# STM32WLE4C8U6 register map
File version: 1.0
Registers are 32-bit, access not given, reset 0x0 unless marked. A register's access mark holds for its fields unless they carry their own. Offsets are from the block's base; [hi:lo] are bit positions; {n}, {i} and the like mark numbered series.

## I2C1
Base 0x40005400
Same registers: I2C2 0x40005800, I2C3 0x40005C00
0x00 CR1
  [23] PECEN, [22] ALERTEN, [21] SMBDEN, [20] SMBHEN, [19] GCEN, [18] WUPEN, [17] NOSTRETCH, [16] SBC, [15] RXDMAEN, [14] TXDMAEN, [31:13] s, [12] ANFOFF, [11:8] DNF, [7] ERRIE, [6] TCIE, [5] STOPIE, [4] NACKIE, [3] ADDRIE, [2] RXIE, [1] TXIE, [0] PE
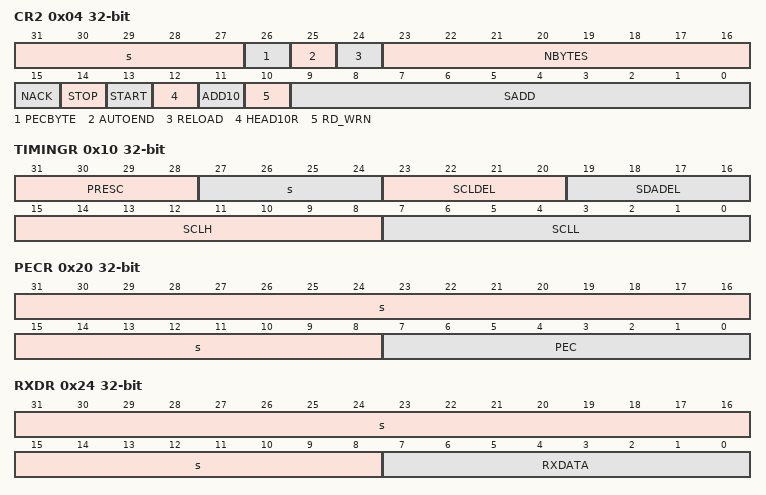
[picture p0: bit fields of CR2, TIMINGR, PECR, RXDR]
0x04 CR2
  [31:27] s, [26] PECBYTE, [25] AUTOEND, [24] RELOAD, [23:16] NBYTES, [15] NACK, [14] STOP, [13] START, [12] HEAD10R, [11] ADD10, [10] RD_WRN, [9:0] SADD
0x08 OAR1
  [15] OA1EN, [31:11] s, [10] OA1MODE, [9:0] OA1
0x0C OAR2
  [15] OA2EN, [10:8] OA2MSK, [7:1] OA2, [31:0] s
0x10 TIMINGR
  [31:28] PRESC, [27:24] s, [23:20] SCLDEL, [19:16] SDADEL, [15:8] SCLH, [7:0] SCLL
0x14 TIMEOUTR
  [31] TEXTEN, [27:16] TIMEOUTB, [15] TIMOUTEN, [30:13] s, [12] TIDLE, [11:0] TIMEOUTA
0x18 ISR
  [23:17] ADDCODE, [16] DIR, [15] BUSY, [31:14] s, [13] ALERT, [12] TIMEOUT, [11] PECERR, [10] OVR, [9] ARLO, [8] BERR, [7] TCR, [6] TC, [5] STOPF, [4] NACKF, [3] ADDR, [2] RXNE, [1] TXIS, [0] TXE
0x1C ICR
  [13] ALERTCF, [12] TIMOUTCF, [11] PECCF, [10] OVRCF, [9] ARLOCF, [8] BERRCF, [5] STOPCF, [4] NACKCF, [3] ADDRCF, [31:0] s
0x20 PECR
  [31:8] s, [7:0] PEC
0x24 RXDR
  [31:8] s, [7:0] RXDATA
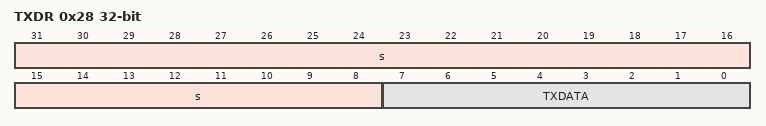
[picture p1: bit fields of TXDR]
0x28 TXDR
  [31:8] s, [7:0] TXDATA

## DAC
Base 0x40007400
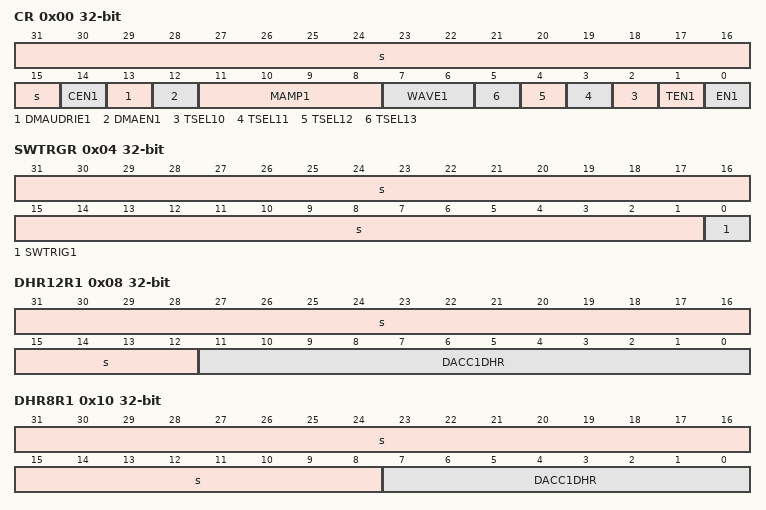
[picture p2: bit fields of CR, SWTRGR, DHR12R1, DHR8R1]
0x00 CR
  [31:15] s, [14] CEN1, [13] DMAUDRIE1, [12] DMAEN1, [11:8] MAMP1, [7:6] WAVE1, [n-8] TSEL{n} (n=10..13), [1] TEN1, [0] EN1
0x04 SWTRGR
  [31:1] s, [0] SWTRIG1
0x08 DHR12R1
  [31:12] s, [11:0] DACC1DHR
0x0C DHR12L1
  [15:4] DACC1DHR, [31:0] s
0x10 DHR8R1
  [31:8] s, [7:0] DACC1DHR
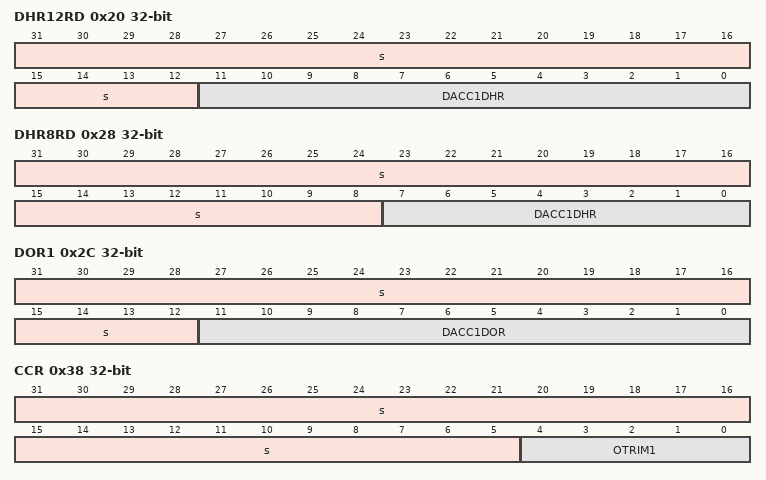
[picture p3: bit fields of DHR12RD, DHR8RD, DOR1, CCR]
0x20 DHR12RD
  [31:12] s, [11:0] DACC1DHR
0x24 DHR12LD
  [15:4] DACC1DHR, [31:0] s
0x28 DHR8RD
  [31:8] s, [7:0] DACC1DHR
0x2C DOR1
  [31:12] s, [11:0] DACC1DOR
0x34 SR
  [15] BWST1, [14] CAL_FLAG1, [13] DMAUDR1, [31:0] s
0x38 CCR
  [31:5] s, [4:0] OTRIM1
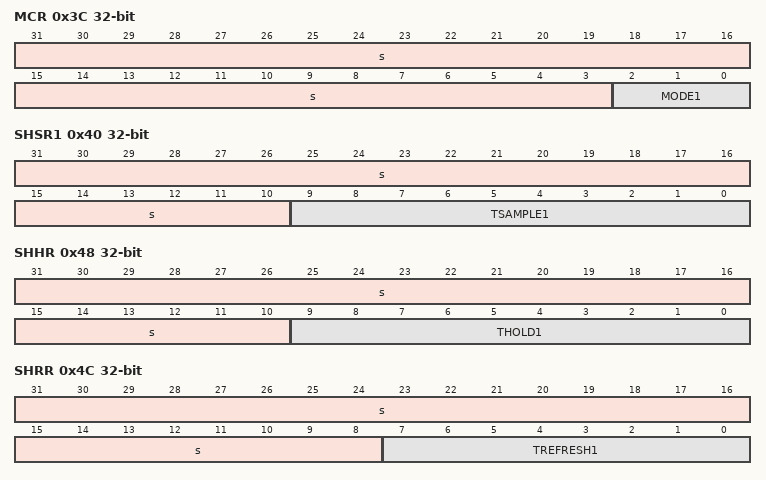
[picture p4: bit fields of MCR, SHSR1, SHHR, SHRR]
0x3C MCR
  [31:3] s, [2:0] MODE1
0x40 SHSR1
  [31:10] s, [9:0] TSAMPLE1
0x48 SHHR
  [31:10] s, [9:0] THOLD1
0x4C SHRR
  [31:8] s, [7:0] TREFRESH1

## LPTIM1
Base 0x40007C00
0x00 CR1
  [11] UIFREMAP, [31:10] s, [9:8] CKD, [7] ARPE, [6:5] CMS, [4] DIR, [3] OPM, [2] URS, [1] UDIS, [0] CEN
0x04 CR2
  [23:20] MMS2, [2n+6] OIS{n} (n=1..6), [13] OIS3N, [11] OIS2N, [9] OIS1N, [7] TI1S, [6:4] MMS, [3] CCDS, [2] CCUS, [31:1] s, [0] CCPC
0x08 SMCR
  [31:17] s, [15] ETP, [14] ECE, [13:12] ETPS, [11:8] ETF, [7] MSM, [21:4] TS, [3] OCCS, [16:0] SMS
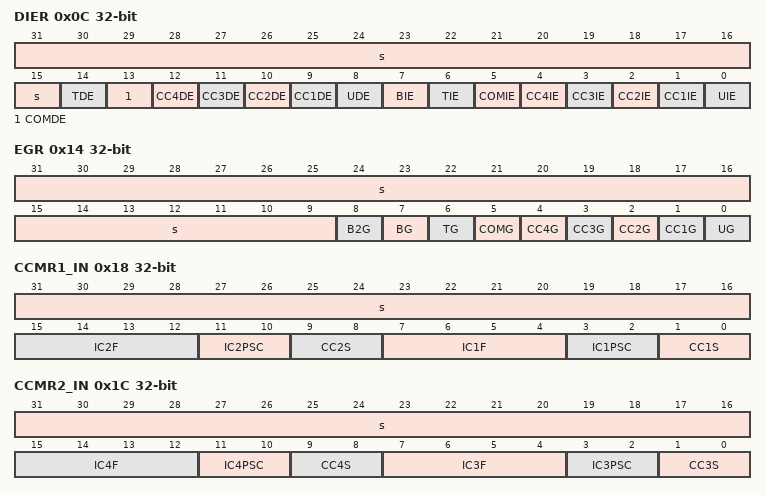
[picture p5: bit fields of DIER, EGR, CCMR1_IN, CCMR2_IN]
0x0C DIER
  [31:15] s, [14] TDE, [13] COMDE, [n+8] CC{n}DE (n=1..4), [8] UDE, [7] BIE, [6] TIE, [5] COMIE, [n] CC{n}IE (n=1..4), [0] UIE
0x10 SR
  [17] CC6IF, [16] CC5IF, [31:14] s, [13] SBIF, [n+8] CC{n}OF (n=1..4), [8] B2IF, [7] BIF, [6] TIF, [5] COMIF, [n] CC{n}IF (n=1..4), [0] UIF
0x14 EGR
  [31:9] s, [8] B2G, [7] BG, [6] TG, [5] COMG, [n] CC{n}G (n=1..4), [0] UG
0x18 CCMR1_OUT
  [31:17] s, [15] OC2CE, [24:12] OC2M, [11] OC2PE, [10] OC2FE, [9:8] CC2S, [7] OC1CE, [16:4] OC1M, [3] OC1PE, [2] OC1FE, [1:0] CC1S
0x18 CCMR1_IN
  [31:16] s, [15:12] IC2F, [11:10] IC2PSC, [9:8] CC2S, [7:4] IC1F, [3:2] IC1PSC, [1:0] CC1S
0x1C CCMR2_OUT
  [31:17] s, [15] OC4CE, [24:12] OC4M, [11] OC4PE, [10] OC4FE, [9:8] CC4S, [7] OC3CE, [16:4] OC3M, [3] OC3PE, [2] OC3FE, [1:0] CC3S
0x1C CCMR2_IN
  [31:16] s, [15:12] IC4F, [11:10] IC4PSC, [9:8] CC4S, [7:4] IC3F, [3:2] IC3PSC, [1:0] CC3S
0x20 CCER
  [4n-3] CC{n}P (n=1..6), [4n-4] CC{n}E (n=1..6), [4n-1] CC{n}NP (n=1..4), [31:14] s, [10] CC3NE, [6] CC2NE, [2] CC1NE
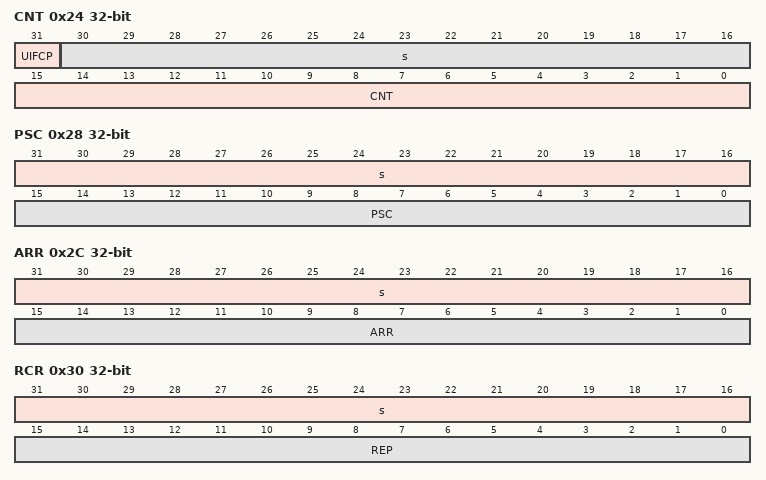
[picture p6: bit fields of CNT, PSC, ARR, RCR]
0x24 CNT
  [31] UIFCP, [30:16] s, [15:0] CNT
0x28 PSC
  [31:16] s, [15:0] PSC
0x2C ARR
  [31:16] s, [15:0] ARR
0x30 RCR
  [31:16] s, [15:0] REP
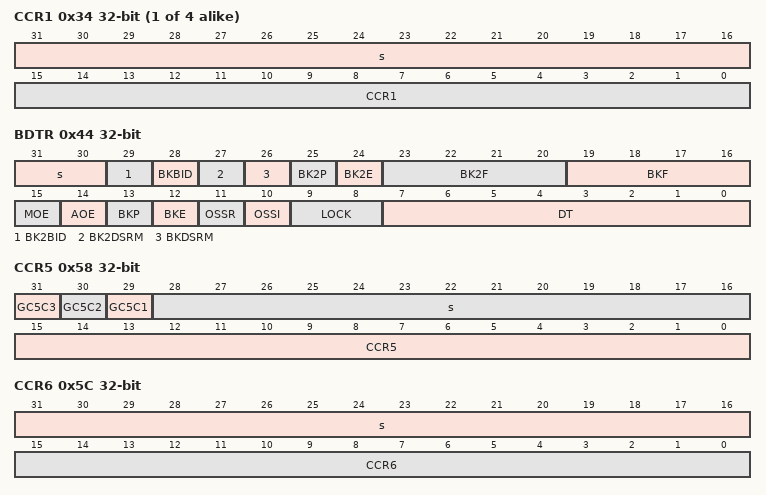
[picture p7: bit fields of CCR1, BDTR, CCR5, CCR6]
{0x30+4i} CCR{i} (i=1..4)
  [31:16] s, [15:0] CCR{i}
0x44 BDTR
  [31:30] s, [29] BK2BID, [28] BKBID, [27] BK2DSRM, [26] BKDSRM, [25] BK2P, [24] BK2E, [23:20] BK2F, [19:16] BKF, [15] MOE, [14] AOE, [13] BKP, [12] BKE, [11] OSSR, [10] OSSI, [9:8] LOCK, [7:0] DT
0x48 DCR
  [12:8] DBL, [31:5] s, [4:0] DBA
0x4C DMAR
  [31:0] DMAB
0x50 OR1
  [4] TI1_RMP, [31:2] s, [1:0] TIM1_ETR_ADC_RMP
0x54 CCMR3_OUT
  [15] OC6CE, [24:12] OC6M, [11] OC6PE, [10] OC6FE, [7] OC5CE, [16:4] OC5M, [3] OC5PE, [2] OC5FE, [31:0] s
0x58 CCR5
  [31] GC5C3, [30] GC5C2, [29] GC5C1, [28:16] s, [15:0] CCR5
0x5C CCR6
  [31:16] s, [15:0] CCR6
0x60 AF1
  [17:14] sETRSEL, [11] BKCMP2P, [10] BKCMP1P, [9] BKINP, [31:3] s, [2] BKCMP2E, [1] BKCMP1E, [0] BKINE
0x64 AF2
  [11] BK2CMP2P, [10] BK2CMP1P, [9] BK2INP, [31:3] s, [2] BK2CMP2E, [1] BK2CMP1E, [0] BK2INE
0x68 TISEL
  [8n-5:8n-8] TI{n}SEL (n=1..4), [31:4] s

## TIM1
Base 0x40012C00
Registers as LPTIM1; these are added or differ:
0x50 OR1
  [4] TI1_RMP, [31:2] s, [1:0] TIM1_ETR_ADC_RMP
